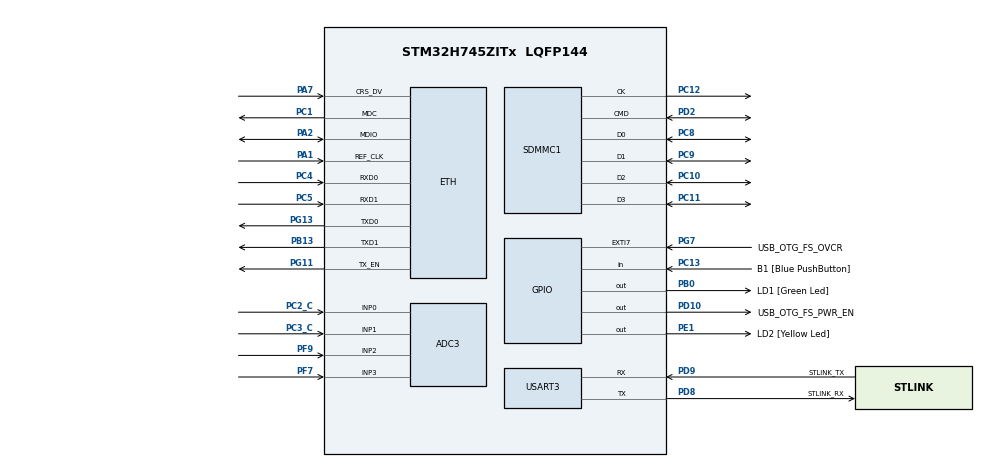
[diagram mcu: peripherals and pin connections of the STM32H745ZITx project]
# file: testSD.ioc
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ADC3.Channel-0\#ChannelRegularConversion=ADC_CHANNEL_0
ADC3.Channel-1\#ChannelRegularConversion=ADC_CHANNEL_1
ADC3.Channel-2\#ChannelRegularConversion=ADC_CHANNEL_2
ADC3.Channel-3\#ChannelRegularConversion=ADC_CHANNEL_3
ADC3.ClockPrescaler=ADC_CLOCK_ASYNC_DIV2
ADC3.ContinuousConvMode=ENABLE
ADC3.ConversionDataManagement=ADC_CONVERSIONDATA_DMA_CIRCULAR
ADC3.NbrOfConversion=4
ADC3.NbrOfConversionFlag=1
ADC3.OffsetNumber-0\#ChannelRegularConversion=ADC_OFFSET_NONE
ADC3.OffsetNumber-1\#ChannelRegularConversion=ADC_OFFSET_NONE
ADC3.OffsetNumber-2\#ChannelRegularConversion=ADC_OFFSET_NONE
ADC3.OffsetNumber-3\#ChannelRegularConversion=ADC_OFFSET_NONE
ADC3.OffsetSignedSaturation-0\#ChannelRegularConversion=DISABLE
ADC3.OffsetSignedSaturation-1\#ChannelRegularConversion=DISABLE
ADC3.OffsetSignedSaturation-2\#ChannelRegularConversion=DISABLE
ADC3.OffsetSignedSaturation-3\#ChannelRegularConversion=DISABLE
ADC3.Rank-0\#ChannelRegularConversion=1
ADC3.Rank-1\#ChannelRegularConversion=2
ADC3.Rank-2\#ChannelRegularConversion=3
ADC3.Rank-3\#ChannelRegularConversion=4
ADC3.SamplingTime-0\#ChannelRegularConversion=ADC_SAMPLETIME_387CYCLES_5
ADC3.SamplingTime-1\#ChannelRegularConversion=ADC_SAMPLETIME_387CYCLES_5
ADC3.SamplingTime-2\#ChannelRegularConversion=ADC_SAMPLETIME_387CYCLES_5
ADC3.SamplingTime-3\#ChannelRegularConversion=ADC_SAMPLETIME_387CYCLES_5
CORTEX_M7.AccessPermission-Cortex_Memory_Protection_Unit_Region0_Settings=MPU_REGION_FULL_ACCESS
CORTEX_M7.AccessPermission-Cortex_Memory_Protection_Unit_Region1_Settings=MPU_REGION_FULL_ACCESS
CORTEX_M7.AccessPermission-Cortex_Memory_Protection_Unit_Region2_Settings=MPU_REGION_FULL_ACCESS
CORTEX_M7.BaseAddress-Cortex_Memory_Protection_Unit_Region0_Settings=0x24000000
CORTEX_M7.BaseAddress-Cortex_Memory_Protection_Unit_Region1_Settings=0x30040000
CORTEX_M7.BaseAddress-Cortex_Memory_Protection_Unit_Region2_Settings=0x30044000
CORTEX_M7.CPU_DCache=Enabled
CORTEX_M7.CPU_ICache=Enabled
CORTEX_M7.Enable-Cortex_Memory_Protection_Unit_Region0_Settings=MPU_REGION_ENABLE
CORTEX_M7.Enable-Cortex_Memory_Protection_Unit_Region1_Settings=MPU_REGION_ENABLE
CORTEX_M7.Enable-Cortex_Memory_Protection_Unit_Region2_Settings=MPU_REGION_ENABLE
CORTEX_M7.IsBufferable-Cortex_Memory_Protection_Unit_Region1_Settings=MPU_ACCESS_BUFFERABLE
CORTEX_M7.IsCacheable-Cortex_Memory_Protection_Unit_Region0_Settings=MPU_ACCESS_NOT_CACHEABLE
CORTEX_M7.IsShareable-Cortex_Memory_Protection_Unit_Region2_Settings=MPU_ACCESS_SHAREABLE
CORTEX_M7.MPU_Control=MPU_PRIVILEGED_DEFAULT
CORTEX_M7.Size-Cortex_Memory_Protection_Unit_Region0_Settings=MPU_REGION_SIZE_512KB
CORTEX_M7.Size-Cortex_Memory_Protection_Unit_Region1_Settings=MPU_REGION_SIZE_256B
CORTEX_M7.Size-Cortex_Memory_Protection_Unit_Region2_Settings=MPU_REGION_SIZE_32KB
CORTEX_M7.TypeExtField-Cortex_Memory_Protection_Unit_Region0_Settings=MPU_TEX_LEVEL0
CORTEX_M7.TypeExtField-Cortex_Memory_Protection_Unit_Region2_Settings=MPU_TEX_LEVEL1
CortexM4.IPs=FATFS_M4\:I,FREERTOS_M4\:I,IWDG2\:I,RCC,WWDG2\:I,DMA,BDMA,MDMA,NVIC2\:I,USART3,DEBUG,PDM2PCM_M4\:I,PWR,RESMGR_UTILITY,SYS_M4\:I,USB_DEVICE_M4\:I,USB_HOST_M4\:I,CORTEX_M4\:I,OPENAMP_M4\:I,VREFBUF
CortexM7.IPs=FATFS_M7\:I,FREERTOS_M7\:I,IWDG1\:I,RCC\:I,WWDG1\:I,DMA\:I,BDMA\:I,MDMA\:I,NVIC1\:I,SYS\:I,USART3\:I,USB_OTG_FS\:I,ETH\:I,CORTEX_M7\:I,DEBUG\:I,PDM2PCM_M7\:I,PWR\:I,RESMGR_UTILITY\:I,USB_DEVICE_M7\:I,USB_HOST_M7\:I,OPENAMP_M7\:I,VREFBUF\:I,SDMMC1\:I,SDMMC2\:I,ADC3\:I,LWIP\:I
Dma.ADC3.0.Direction=DMA_PERIPH_TO_MEMORY
Dma.ADC3.0.EventEnable=DISABLE
Dma.ADC3.0.FIFOMode=DMA_FIFOMODE_DISABLE
Dma.ADC3.0.Instance=DMA1_Stream0
Dma.ADC3.0.MemDataAlignment=DMA_MDATAALIGN_WORD
Dma.ADC3.0.MemInc=DMA_MINC_ENABLE
Dma.ADC3.0.Mode=DMA_CIRCULAR
Dma.ADC3.0.PeriphDataAlignment=DMA_PDATAALIGN_WORD
Dma.ADC3.0.PeriphInc=DMA_PINC_DISABLE
Dma.ADC3.0.Polarity=HAL_DMAMUX_REQ_GEN_RISING
Dma.ADC3.0.Priority=DMA_PRIORITY_LOW
Dma.ADC3.0.RequestNumber=1
Dma.ADC3.0.SignalID=NONE
Dma.ADC3.0.SyncEnable=DISABLE
Dma.ADC3.0.SyncPolarity=HAL_DMAMUX_SYNC_NO_EVENT
Dma.ADC3.0.SyncRequestNumber=1
Dma.ADC3.0.SyncSignalID=NONE
Dma.Request0=ADC3
ETH.MediaInterface=HAL_ETH_RMII_MODE
FATFS_M7.USE_DMA_CODE_SD=1
FATFS_M7._FS_EXFAT=1
FATFS_M7._MAX_SS=4096
FATFS_M7._USE_LFN=2
FREERTOS_M7.Tasks01=defaultTask,24,128,StartDefaultTask,Default,NULL,Dynamic,NULL,NULL
LWIP.CMSIS_VERSION-Enabled=1
LWIP.MEM_SIZE=1600
LWIP.Version=v2.1.2_Cube
Mcu.Family=STM32H7
Mcu.Name=STM32H745ZITx
Mcu.Package=LQFP144
NVIC1.DMA1_Stream0_IRQn=true\:5\:0\:false\:false\:true\:true\:false\:true
NVIC1.ETH_IRQn=true\:5\:0\:false\:false\:true\:true\:true\:true
NVIC1.PriorityGroup=NVIC_PRIORITYGROUP_4
NVIC1.RCC_IRQn=true\:5\:0\:false\:false\:true\:true\:true\:false
NVIC1.SDMMC1_IRQn=true\:5\:0\:false\:false\:true\:true\:true\:true
NVIC2.PriorityGroup=NVIC_PRIORITYGROUP_4
PA1.Mode=RMII
PA1.PinAttribute=CortexM7
PA1.Signal=ETH_REF_CLK
PA11.PinAttribute=CortexM7
PA11.Signal=USB_OTG_FS_DM
PA12.PinAttribute=CortexM7
PA12.Signal=USB_OTG_FS_DP
PA2.Mode=RMII
PA2.PinAttribute=CortexM7
PA2.Signal=ETH_MDIO
PA7.Mode=RMII
PA7.PinAttribute=CortexM7
PA7.Signal=ETH_CRS_DV
PA8.PinAttribute=CortexM7
PA8.Signal=USB_OTG_FS_SOF
PA9.PinAttribute=CortexM7
PA9.Signal=USB_OTG_FS_VBUS
PB0.GPIO_Label=LD1 [Green Led]
PB0.PinAttribute=Free
PB0.Signal=GPIO_Output
PB13.Mode=RMII
PB13.PinAttribute=CortexM7
PB13.Signal=ETH_TXD1
PC1.Mode=RMII
PC1.PinAttribute=CortexM7
PC1.Signal=ETH_MDC
PC10.Mode=SD_4_bits_Wide_bus
PC10.PinAttribute=CortexM7
PC10.Signal=SDMMC1_D2
PC11.Mode=SD_4_bits_Wide_bus
PC11.PinAttribute=CortexM7
PC11.Signal=SDMMC1_D3
PC12.Mode=SD_4_bits_Wide_bus
PC12.PinAttribute=CortexM7
PC12.Signal=SDMMC1_CK
PC13.GPIO_Label=B1 [Blue PushButton]
PC13.PinAttribute=Free
PC13.Signal=GPIO_Input
PC14-OSC32_IN\ (OSC32_IN).Mode=LSE-External-Oscillator
PC14-OSC32_IN\ (OSC32_IN).PinAttribute=CortexM7
PC14-OSC32_IN\ (OSC32_IN).Signal=RCC_OSC32_IN
PC15-OSC32_OUT\ (OSC32_OUT).Mode=LSE-External-Oscillator
PC15-OSC32_OUT\ (OSC32_OUT).PinAttribute=CortexM7
PC15-OSC32_OUT\ (OSC32_OUT).Signal=RCC_OSC32_OUT
PC2_C.Mode=IN0-Single-Ended
PC2_C.PinAttribute=CortexM7
PC2_C.Signal=ADC3_INP0
PC3_C.Mode=IN1-Single-Ended
PC3_C.PinAttribute=CortexM7
PC3_C.Signal=ADC3_INP1
PC4.Mode=RMII
PC4.PinAttribute=CortexM7
PC4.Signal=ETH_RXD0
PC5.Mode=RMII
PC5.PinAttribute=CortexM7
PC5.Signal=ETH_RXD1
PC8.Mode=SD_4_bits_Wide_bus
PC8.PinAttribute=CortexM7
PC8.Signal=SDMMC1_D0
PC9.Mode=SD_4_bits_Wide_bus
PC9.PinAttribute=CortexM7
PC9.Signal=SDMMC1_D1
PD10.GPIO_Label=USB_OTG_FS_PWR_EN
PD10.PinAttribute=Free
PD10.Signal=GPIO_Output
PD2.Mode=SD_4_bits_Wide_bus
PD2.PinAttribute=CortexM7
PD2.Signal=SDMMC1_CMD
PD8.GPIO_Label=STLINK_RX
PD8.Mode=Asynchronous
PD8.PinAttribute=CortexM7
PD8.Signal=USART3_TX
PD9.GPIO_Label=STLINK_TX
PD9.Mode=Asynchronous
PD9.PinAttribute=CortexM7
PD9.Signal=USART3_RX
PE1.GPIO_Label=LD2 [Yellow Led]
PE1.PinAttribute=Free
PE1.Signal=GPIO_Output
PF7.Mode=IN3-Single-Ended
PF7.PinAttribute=CortexM7
PF7.Signal=ADC3_INP3
PF9.Mode=IN2-Single-Ended
PF9.PinAttribute=CortexM7
PF9.Signal=ADC3_INP2
PG11.Mode=RMII
PG11.PinAttribute=CortexM7
PG11.Signal=ETH_TX_EN
PG13.Mode=RMII
PG13.PinAttribute=CortexM7
PG13.Signal=ETH_TXD0
PG7.GPIO_Label=USB_OTG_FS_OVCR
PG7.PinAttribute=Free
PG7.Signal=GPXTI7
PH0-OSC_IN\ (PH0).Mode=HSE-External-Clock-Source
PH0-OSC_IN\ (PH0).PinAttribute=CortexM7
PH0-OSC_IN\ (PH0).Signal=RCC_OSC_IN
PH1-OSC_OUT\ (PH1).PinAttribute=CortexM7
PH1-OSC_OUT\ (PH1).Signal=RCC_OSC_OUT
ProjectManager.HeapSize=0x2000
ProjectManager.StackSize=0x4000
ProjectManager.TargetToolchain=STM32CubeIDE
RCC.ADCFreq_Value=150000000
RCC.APB1Freq_Value=120000000
RCC.APB2Freq_Value=120000000
RCC.APB3Freq_Value=120000000
RCC.APB4Freq_Value=120000000
RCC.CortexFreq_Value=480000000
RCC.D1PPRE=RCC_APB3_DIV2
RCC.D2PPRE1=RCC_APB1_DIV2
RCC.D2PPRE2=RCC_APB2_DIV2
RCC.D3PPRE=RCC_APB4_DIV2
RCC.DIVM1=4
RCC.DIVM2=4
RCC.DIVM3=22
RCC.DIVN1=60
RCC.DIVN2=9
RCC.DIVN3=169
RCC.DIVP2=1
RCC.DIVQ1=4
RCC.DIVQ3=4
RCC.DIVR2=1
RCC.HCLKFreq_Value=240000000
RCC.HPRE=RCC_HCLK_DIV2
RCC.PLL2FRACN=3072
RCC.PLL3FRACN=0
RCC.PLLFRACN=0
RCC.SDMMC1CLockSelection=RCC_SDMMCCLKSOURCE_PLL2
RCC.SYSCLKFreq_VALUE=480000000
RCC.SYSCLKSource=RCC_SYSCLKSOURCE_PLLCLK
RCC.SupplySource=PWR_DIRECT_SMPS_SUPPLY
RCC.USBCLockSelection=RCC_USBCLKSOURCE_PLL3
RCC.USBFreq_Value=122909090.9090909
SDMMC1.ClockDiv=8
USART3.VirtualMode-Asynchronous=VM_ASYNC
VP_FATFS_M7_VS_SDIO.Mode=SDIO
VP_FREERTOS_M7_VS_CMSIS_V2.Mode=CMSIS_V2
VP_LWIP_VS_Enabled.Mode=Enabled
VP_SYS_M4_VS_Systick.Mode=SysTick
board=NUCLEO-H745ZI-Q

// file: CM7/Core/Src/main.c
/* USER CODE BEGIN Header */
/**
  ******************************************************************************
  * @file           : main.c
  * @brief          : Main program body
  ******************************************************************************
  * @attention
  *
  * <h2><center>&copy; Copyright (c) 2020 STMicroelectronics.
  * All rights reserved.</center></h2>
  *
  * This software component is licensed by ST under Ultimate Liberty license
  * SLA0044, the "License"; You may not use this file except in compliance with
  * the License. You may obtain a copy of the License at:
  *                             www.st.com/SLA0044
  *
  ******************************************************************************
  */
/* USER CODE END Header */
#include "main.h"
#include "cmsis_os.h"
#include "fatfs.h"
#include "lwip.h"

/* USER CODE BEGIN PD */

#define HSEM_ID_0 (0U) /* HW semaphore 0*/
/* USER CODE END PD */

/* USER CODE BEGIN PM */

FATFS myFatFS;
FIL myFile;
UINT myBytes;
/* USER CODE END PM */

ADC_HandleTypeDef hadc3;
DMA_HandleTypeDef hdma_adc3;

SD_HandleTypeDef hsd1;

UART_HandleTypeDef huart3;

/* Definitions for defaultTask */
osThreadId_t defaultTaskHandle;
const osThreadAttr_t defaultTask_attributes = {
  .name = "defaultTask",
  .priority = (osPriority_t) osPriorityNormal,
  .stack_size = 128 * 4
};

void SystemClock_Config(void);
static void MPU_Config(void);
static void MX_GPIO_Init(void);
static void MX_DMA_Init(void);
static void MX_SDMMC1_SD_Init(void);
static void MX_USART3_UART_Init(void);
static void MX_ADC3_Init(void);
void StartDefaultTask(void *argument);

int main(void)
{
/* USER CODE BEGIN Boot_Mode_Sequence_0 */
  int32_t timeout;
/* USER CODE END Boot_Mode_Sequence_0 */

  /* MPU Configuration--------------------------------------------------------*/
  MPU_Config();

  /* Enable I-Cache---------------------------------------------------------*/
  SCB_EnableICache();

  /* Enable D-Cache---------------------------------------------------------*/
  SCB_EnableDCache();

/* USER CODE BEGIN Boot_Mode_Sequence_1 */
  /* Wait until CPU2 boots and enters in stop mode or timeout*/
  timeout = 0xFFFF;
  while((__HAL_RCC_GET_FLAG(RCC_FLAG_D2CKRDY) != RESET) && (timeout-- > 0));
  if ( timeout < 0 )
  {
  Error_Handler();
  }
/* USER CODE END Boot_Mode_Sequence_1 */
  /* MCU Configuration--------------------------------------------------------*/

  /* Reset of all peripherals, Initializes the Flash interface and the Systick. */
  HAL_Init();

  /* Configure the system clock */
  SystemClock_Config();
/* USER CODE BEGIN Boot_Mode_Sequence_2 */
/* When system initialization is finished, Cortex-M7 will release Cortex-M4 by means of
HSEM notification */
/*HW semaphore Clock enable*/
__HAL_RCC_HSEM_CLK_ENABLE();
/*Take HSEM */
HAL_HSEM_FastTake(HSEM_ID_0);
/*Release HSEM in order to notify the CPU2(CM4)*/
HAL_HSEM_Release(HSEM_ID_0,0);
/* wait until CPU2 wakes up from stop mode */
timeout = 0xFFFF;
while((__HAL_RCC_GET_FLAG(RCC_FLAG_D2CKRDY) == RESET) && (timeout-- > 0));
if ( timeout < 0 )
{
Error_Handler();
}
/* USER CODE END Boot_Mode_Sequence_2 */

  /* Initialize all configured peripherals */
  MX_GPIO_Init();
  MX_DMA_Init();
  MX_SDMMC1_SD_Init();
  MX_USART3_UART_Init();
  MX_FATFS_Init();
  MX_ADC3_Init();
  /* USER CODE BEGIN 2 */

  SCB_CleanInvalidateDCache();

  FRESULT res;

  //	BYTE work[_MAX_SS];
  //  res = f_mkfs(SDPath, FM_ANY, 0, work, sizeof(work));

  res = f_mount(&SDFatFS, "", 0);//f_mount(&SDFatFS, SDPath, 1);

  /* open the file */
  res = f_open(&myFile, "test.txt", FA_CREATE_ALWAYS | FA_WRITE);

  /* write to a file */
  char myData[] = "Hello from STM32H7, sdio in 4 bits mode";
  f_write(&myFile, &myData, sizeof(myData), (void *)&myBytes);

  /* close the file */
  f_close(&myFile);

  /*
	if(f_mount(&SDFatFS, (TCHAR const*)SDPath,0) == FR_OK){

			uint8_t msg[] = "SDCard - mounted\r\n";
			HAL_UART_Transmit(&huart3, msg, strlen((char *)msg), HAL_MAX_DELAY);

			char myFileName[] = "TestSTM.txt";

			if(f_open(&SDFile, myFileName, FA_CREATE_ALWAYS | FA_WRITE) == FR_OK){

				uint8_t msg[] = "SDCard - file opened\r\n";
				HAL_UART_Transmit(&huart3, msg, strlen((char *)msg), HAL_MAX_DELAY);

				char myData[] = "Hello from STM32H7, sdio in 4 bits mode";

				if(f_write(&myFile, myData, sizeof(myData), &myBytes) == FR_OK){

						uint8_t msg[] = "SDCard - write data\r\n";
						HAL_UART_Transmit(&huart3, msg, strlen((char *)msg), HAL_MAX_DELAY);
				}

				f_close(&myFile);

			}
	}else{

			uint8_t msg[] = "SDCard - not mounted\r\n";
			HAL_UART_Transmit(&huart3, msg, strlen((char *)msg), HAL_MAX_DELAY);
	}
  */

  /* USER CODE END 2 */

  /* Init scheduler */
  osKernelInitialize();

  /* Create the thread(s) */
  /* creation of defaultTask */
  defaultTaskHandle = osThreadNew(StartDefaultTask, NULL, &defaultTask_attributes);

  /* Start scheduler */
  osKernelStart();

  /* We should never get here as control is now taken by the scheduler */
  /* Infinite loop */
  while (1)
  {

  }
}

void SystemClock_Config(void)
{
  RCC_OscInitTypeDef RCC_OscInitStruct = {0};
  RCC_ClkInitTypeDef RCC_ClkInitStruct = {0};
  RCC_PeriphCLKInitTypeDef PeriphClkInitStruct = {0};

  /** Supply configuration update enable
  */
  HAL_PWREx_ConfigSupply(PWR_DIRECT_SMPS_SUPPLY);
  /** Configure the main internal regulator output voltage
  */
  __HAL_PWR_VOLTAGESCALING_CONFIG(PWR_REGULATOR_VOLTAGE_SCALE0);

  while(!__HAL_PWR_GET_FLAG(PWR_FLAG_VOSRDY)) {}
  /** Macro to configure the PLL clock source
  */
  __HAL_RCC_PLL_PLLSOURCE_CONFIG(RCC_PLLSOURCE_HSI);
  /** Initializes the RCC Oscillators according to the specified parameters
  * in the RCC_OscInitTypeDef structure.
  */
  RCC_OscInitStruct.OscillatorType = RCC_OSCILLATORTYPE_HSI;
  RCC_OscInitStruct.HSIState = RCC_HSI_DIV1;
  RCC_OscInitStruct.HSICalibrationValue = RCC_HSICALIBRATION_DEFAULT;
  RCC_OscInitStruct.PLL.PLLState = RCC_PLL_ON;
  RCC_OscInitStruct.PLL.PLLSource = RCC_PLLSOURCE_HSI;
  RCC_OscInitStruct.PLL.PLLM = 4;
  RCC_OscInitStruct.PLL.PLLN = 60;
  RCC_OscInitStruct.PLL.PLLP = 2;
  RCC_OscInitStruct.PLL.PLLQ = 4;
  RCC_OscInitStruct.PLL.PLLR = 2;
  RCC_OscInitStruct.PLL.PLLRGE = RCC_PLL1VCIRANGE_3;
  RCC_OscInitStruct.PLL.PLLVCOSEL = RCC_PLL1VCOWIDE;
  RCC_OscInitStruct.PLL.PLLFRACN = 0;
  if (HAL_RCC_OscConfig(&RCC_OscInitStruct) != HAL_OK)
  {
    Error_Handler();
  }
  /** Initializes the CPU, AHB and APB buses clocks
  */
  RCC_ClkInitStruct.ClockType = RCC_CLOCKTYPE_HCLK|RCC_CLOCKTYPE_SYSCLK
                              |RCC_CLOCKTYPE_PCLK1|RCC_CLOCKTYPE_PCLK2
                              |RCC_CLOCKTYPE_D3PCLK1|RCC_CLOCKTYPE_D1PCLK1;
  RCC_ClkInitStruct.SYSCLKSource = RCC_SYSCLKSOURCE_PLLCLK;
  RCC_ClkInitStruct.SYSCLKDivider = RCC_SYSCLK_DIV1;
  RCC_ClkInitStruct.AHBCLKDivider = RCC_HCLK_DIV2;
  RCC_ClkInitStruct.APB3CLKDivider = RCC_APB3_DIV2;
  RCC_ClkInitStruct.APB1CLKDivider = RCC_APB1_DIV2;
  RCC_ClkInitStruct.APB2CLKDivider = RCC_APB2_DIV2;
  RCC_ClkInitStruct.APB4CLKDivider = RCC_APB4_DIV2;

  if (HAL_RCC_ClockConfig(&RCC_ClkInitStruct, FLASH_LATENCY_4) != HAL_OK)
  {
    Error_Handler();
  }
  PeriphClkInitStruct.PeriphClockSelection = RCC_PERIPHCLK_USART3|RCC_PERIPHCLK_SDMMC
                              |RCC_PERIPHCLK_ADC;
  PeriphClkInitStruct.PLL2.PLL2M = 4;
  PeriphClkInitStruct.PLL2.PLL2N = 9;
  PeriphClkInitStruct.PLL2.PLL2P = 1;
  PeriphClkInitStruct.PLL2.PLL2Q = 2;
  PeriphClkInitStruct.PLL2.PLL2R = 1;
  PeriphClkInitStruct.PLL2.PLL2RGE = RCC_PLL2VCIRANGE_3;
  PeriphClkInitStruct.PLL2.PLL2VCOSEL = RCC_PLL2VCOMEDIUM;
  PeriphClkInitStruct.PLL2.PLL2FRACN = 3072;
  PeriphClkInitStruct.SdmmcClockSelection = RCC_SDMMCCLKSOURCE_PLL2;
  PeriphClkInitStruct.Usart234578ClockSelection = RCC_USART234578CLKSOURCE_D2PCLK1;
  PeriphClkInitStruct.AdcClockSelection = RCC_ADCCLKSOURCE_PLL2;
  if (HAL_RCCEx_PeriphCLKConfig(&PeriphClkInitStruct) != HAL_OK)
  {
    Error_Handler();
  }
}

static void MX_ADC3_Init(void)
{

  ADC_ChannelConfTypeDef sConfig = {0};

  /** Common config
  */
  hadc3.Instance = ADC3;
  hadc3.Init.ClockPrescaler = ADC_CLOCK_ASYNC_DIV2;
  hadc3.Init.Resolution = ADC_RESOLUTION_16B;
  hadc3.Init.ScanConvMode = ADC_SCAN_ENABLE;
  hadc3.Init.EOCSelection = ADC_EOC_SINGLE_CONV;
  hadc3.Init.LowPowerAutoWait = DISABLE;
  hadc3.Init.ContinuousConvMode = ENABLE;
  hadc3.Init.NbrOfConversion = 4;
  hadc3.Init.DiscontinuousConvMode = DISABLE;
  hadc3.Init.ExternalTrigConv = ADC_SOFTWARE_START;
  hadc3.Init.ExternalTrigConvEdge = ADC_EXTERNALTRIGCONVEDGE_NONE;
  hadc3.Init.ConversionDataManagement = ADC_CONVERSIONDATA_DMA_CIRCULAR;
  hadc3.Init.Overrun = ADC_OVR_DATA_PRESERVED;
  hadc3.Init.LeftBitShift = ADC_LEFTBITSHIFT_NONE;
  hadc3.Init.OversamplingMode = DISABLE;
  if (HAL_ADC_Init(&hadc3) != HAL_OK)
  {
    Error_Handler();
  }
  /** Configure Regular Channel
  */
  sConfig.Channel = ADC_CHANNEL_0;
  sConfig.Rank = ADC_REGULAR_RANK_1;
  sConfig.SamplingTime = ADC_SAMPLETIME_387CYCLES_5;
  sConfig.SingleDiff = ADC_SINGLE_ENDED;
  sConfig.OffsetNumber = ADC_OFFSET_NONE;
  sConfig.Offset = 0;
  sConfig.OffsetSignedSaturation = DISABLE;
  if (HAL_ADC_ConfigChannel(&hadc3, &sConfig) != HAL_OK)
  {
    Error_Handler();
  }
  /** Configure Regular Channel
  */
  sConfig.Channel = ADC_CHANNEL_1;
  sConfig.Rank = ADC_REGULAR_RANK_2;
  if (HAL_ADC_ConfigChannel(&hadc3, &sConfig) != HAL_OK)
  {
    Error_Handler();
  }
  /** Configure Regular Channel
  */
  sConfig.Channel = ADC_CHANNEL_2;
  sConfig.Rank = ADC_REGULAR_RANK_3;
  if (HAL_ADC_ConfigChannel(&hadc3, &sConfig) != HAL_OK)
  {
    Error_Handler();
  }
  /** Configure Regular Channel
  */
  sConfig.Channel = ADC_CHANNEL_3;
  sConfig.Rank = ADC_REGULAR_RANK_4;
  if (HAL_ADC_ConfigChannel(&hadc3, &sConfig) != HAL_OK)
  {
    Error_Handler();
  }

}

static void MX_SDMMC1_SD_Init(void)
{

  hsd1.Instance = SDMMC1;
  hsd1.Init.ClockEdge = SDMMC_CLOCK_EDGE_RISING;
  hsd1.Init.ClockPowerSave = SDMMC_CLOCK_POWER_SAVE_DISABLE;
  hsd1.Init.BusWide = SDMMC_BUS_WIDE_4B;
  hsd1.Init.HardwareFlowControl = SDMMC_HARDWARE_FLOW_CONTROL_DISABLE;
  hsd1.Init.ClockDiv = 8;
  hsd1.Init.TranceiverPresent = SDMMC_TRANSCEIVER_NOT_PRESENT;
  if (HAL_SD_Init(&hsd1) != HAL_OK)
  {
    Error_Handler();
  }

}

static void MX_USART3_UART_Init(void)
{

  huart3.Instance = USART3;
  huart3.Init.BaudRate = 115200;
  huart3.Init.WordLength = UART_WORDLENGTH_8B;
  huart3.Init.StopBits = UART_STOPBITS_1;
  huart3.Init.Parity = UART_PARITY_NONE;
  huart3.Init.Mode = UART_MODE_TX_RX;
  huart3.Init.HwFlowCtl = UART_HWCONTROL_NONE;
  huart3.Init.OverSampling = UART_OVERSAMPLING_16;
  huart3.Init.OneBitSampling = UART_ONE_BIT_SAMPLE_DISABLE;
  huart3.Init.ClockPrescaler = UART_PRESCALER_DIV1;
  huart3.AdvancedInit.AdvFeatureInit = UART_ADVFEATURE_NO_INIT;
  if (HAL_UART_Init(&huart3) != HAL_OK)
  {
    Error_Handler();
  }
  if (HAL_UARTEx_SetTxFifoThreshold(&huart3, UART_TXFIFO_THRESHOLD_1_8) != HAL_OK)
  {
    Error_Handler();
  }
  if (HAL_UARTEx_SetRxFifoThreshold(&huart3, UART_RXFIFO_THRESHOLD_1_8) != HAL_OK)
  {
    Error_Handler();
  }
  if (HAL_UARTEx_DisableFifoMode(&huart3) != HAL_OK)
  {
    Error_Handler();
  }

}

static void MX_DMA_Init(void)
{

  /* DMA controller clock enable */
  __HAL_RCC_DMA1_CLK_ENABLE();

  /* DMA interrupt init */
  /* DMA1_Stream0_IRQn interrupt configuration */
  HAL_NVIC_SetPriority(DMA1_Stream0_IRQn, 5, 0);
  HAL_NVIC_EnableIRQ(DMA1_Stream0_IRQn);

}

static void MX_GPIO_Init(void)
{
  GPIO_InitTypeDef GPIO_InitStruct = {0};

  /* GPIO Ports Clock Enable */
  __HAL_RCC_GPIOC_CLK_ENABLE();
  __HAL_RCC_GPIOF_CLK_ENABLE();
  __HAL_RCC_GPIOH_CLK_ENABLE();
  __HAL_RCC_GPIOA_CLK_ENABLE();
  __HAL_RCC_GPIOB_CLK_ENABLE();
  __HAL_RCC_GPIOD_CLK_ENABLE();
  __HAL_RCC_GPIOG_CLK_ENABLE();

  /*Configure GPIO pins : PA8 PA11 PA12 */
  GPIO_InitStruct.Pin = GPIO_PIN_8|GPIO_PIN_11|GPIO_PIN_12;
  GPIO_InitStruct.Mode = GPIO_MODE_AF_PP;
  GPIO_InitStruct.Pull = GPIO_NOPULL;
  GPIO_InitStruct.Speed = GPIO_SPEED_FREQ_LOW;
  GPIO_InitStruct.Alternate = GPIO_AF10_OTG1_FS;
  HAL_GPIO_Init(GPIOA, &GPIO_InitStruct);

}

void StartDefaultTask(void *argument)
{
  /* init code for LWIP */
  MX_LWIP_Init();
  for(;;)
  {
    osDelay(1);
  }
}

/* MPU Configuration */

void MPU_Config(void)
{
  MPU_Region_InitTypeDef MPU_InitStruct = {0};

  /* Disables the MPU */
  HAL_MPU_Disable();
  /** Initializes and configures the Region and the memory to be protected
  */
  MPU_InitStruct.Enable = MPU_REGION_ENABLE;
  MPU_InitStruct.Number = MPU_REGION_NUMBER0;
  MPU_InitStruct.BaseAddress = 0x24000000;
  MPU_InitStruct.Size = MPU_REGION_SIZE_512KB;
  MPU_InitStruct.SubRegionDisable = 0x0;
  MPU_InitStruct.TypeExtField = MPU_TEX_LEVEL0;
  MPU_InitStruct.AccessPermission = MPU_REGION_FULL_ACCESS;
  MPU_InitStruct.DisableExec = MPU_INSTRUCTION_ACCESS_ENABLE;
  MPU_InitStruct.IsShareable = MPU_ACCESS_NOT_SHAREABLE;
  MPU_InitStruct.IsCacheable = MPU_ACCESS_NOT_CACHEABLE;
  MPU_InitStruct.IsBufferable = MPU_ACCESS_NOT_BUFFERABLE;

  HAL_MPU_ConfigRegion(&MPU_InitStruct);
  /** Initializes and configures the Region and the memory to be protected
  */
  MPU_InitStruct.Enable = MPU_REGION_ENABLE;
  MPU_InitStruct.Number = MPU_REGION_NUMBER1;
  MPU_InitStruct.BaseAddress = 0x30040000;
  MPU_InitStruct.Size = MPU_REGION_SIZE_256B;
  MPU_InitStruct.SubRegionDisable = 0x0;
  MPU_InitStruct.TypeExtField = MPU_TEX_LEVEL0;
  MPU_InitStruct.AccessPermission = MPU_REGION_FULL_ACCESS;
  MPU_InitStruct.DisableExec = MPU_INSTRUCTION_ACCESS_ENABLE;
  MPU_InitStruct.IsShareable = MPU_ACCESS_NOT_SHAREABLE;
  MPU_InitStruct.IsCacheable = MPU_ACCESS_NOT_CACHEABLE;
  MPU_InitStruct.IsBufferable = MPU_ACCESS_BUFFERABLE;

  HAL_MPU_ConfigRegion(&MPU_InitStruct);
  /** Initializes and configures the Region and the memory to be protected
  */
  MPU_InitStruct.Enable = MPU_REGION_ENABLE;
  MPU_InitStruct.Number = MPU_REGION_NUMBER2;
  MPU_InitStruct.BaseAddress = 0x30044000;
  MPU_InitStruct.Size = MPU_REGION_SIZE_32KB;
  MPU_InitStruct.SubRegionDisable = 0x0;
  MPU_InitStruct.TypeExtField = MPU_TEX_LEVEL1;
  MPU_InitStruct.AccessPermission = MPU_REGION_FULL_ACCESS;
  MPU_InitStruct.DisableExec = MPU_INSTRUCTION_ACCESS_ENABLE;
  MPU_InitStruct.IsShareable = MPU_ACCESS_SHAREABLE;
  MPU_InitStruct.IsCacheable = MPU_ACCESS_NOT_CACHEABLE;
  MPU_InitStruct.IsBufferable = MPU_ACCESS_NOT_BUFFERABLE;

  HAL_MPU_ConfigRegion(&MPU_InitStruct);
  /* Enables the MPU */
  HAL_MPU_Enable(MPU_PRIVILEGED_DEFAULT);

}

void Error_Handler(void)
{
}

/************************ (C) COPYRIGHT STMicroelectronics *****END OF FILE****/
